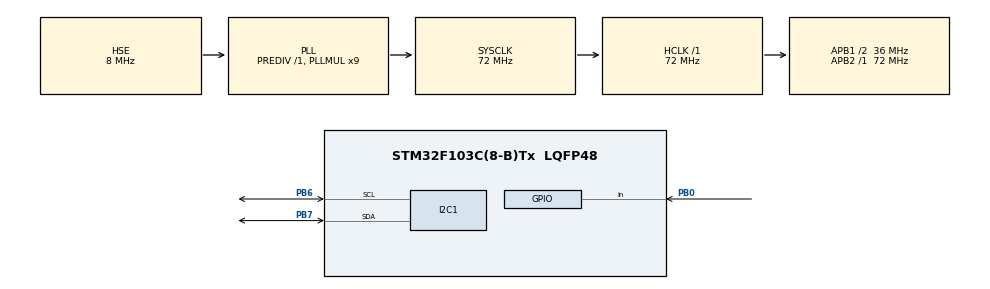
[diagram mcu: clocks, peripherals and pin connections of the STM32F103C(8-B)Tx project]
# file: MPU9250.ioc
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I2C1.I2C_Mode=I2C_Fast
Mcu.Family=STM32F1
Mcu.Name=STM32F103C(8-B)Tx
Mcu.Package=LQFP48
NVIC.PriorityGroup=NVIC_PRIORITYGROUP_4
NVIC.TIM2_IRQn=true\:0\:0\:false\:false\:true\:true\:true\:true
PA13.Mode=Serial_Wire
PA13.Signal=SYS_JTMS-SWDIO
PA14.Mode=Serial_Wire
PA14.Signal=SYS_JTCK-SWCLK
PB0.GPIO_PuPd=GPIO_PULLUP
PB0.Signal=GPIO_Input
PB6.Mode=I2C
PB6.Signal=I2C1_SCL
PB7.Mode=I2C
PB7.Signal=I2C1_SDA
PD0-OSC_IN.Mode=HSE-External-Oscillator
PD0-OSC_IN.Signal=RCC_OSC_IN
PD1-OSC_OUT.Mode=HSE-External-Oscillator
PD1-OSC_OUT.Signal=RCC_OSC_OUT
ProjectManager.HeapSize=0x200
ProjectManager.StackSize=0x400
ProjectManager.TargetToolchain=STM32CubeIDE
RCC.AHBFreq_Value=72000000
RCC.APB1CLKDivider=RCC_HCLK_DIV2
RCC.APB1Freq_Value=36000000
RCC.APB1TimFreq_Value=72000000
RCC.APB2Freq_Value=72000000
RCC.APB2TimFreq_Value=72000000
RCC.HCLKFreq_Value=72000000
RCC.PLLMUL=RCC_PLL_MUL9
RCC.PLLSourceVirtual=RCC_PLLSOURCE_HSE
RCC.SYSCLKFreq_VALUE=72000000
RCC.SYSCLKSource=RCC_SYSCLKSOURCE_PLLCLK
RCC.USBFreq_Value=72000000
TIM2.AutoReloadPreload=TIM_AUTORELOAD_PRELOAD_ENABLE
TIM2.Period=36000
TIM2.Prescaler=1000
VP_TIM2_VS_ClockSourceINT.Mode=Internal
board=custom

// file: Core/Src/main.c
/* USER CODE BEGIN Header */
/**
  ******************************************************************************
  * @file           : main.c
  * @brief          : Main program body
  ******************************************************************************
  * @attention
  *
  * Copyright (c) 2022 STMicroelectronics.
  * All rights reserved.
  *
  * This software is licensed under terms that can be found in the LICENSE file
  * in the root directory of this software component.
  * If no LICENSE file comes with this software, it is provided AS-IS.
  *
  ******************************************************************************
  */
/* USER CODE END Header */
#include "main.h"

/* USER CODE BEGIN Includes */
#include "MPU9250.h"
#include "arrebote.h"
#include <math.h>
/* USER CODE END Includes */

/* USER CODE BEGIN PD */
#define CANT_MUESTRAS	200
#define VAL_MAX			16384
#define K				57.295779//rad a grad

#define PULSADOR_ACTIVO_BAJO	(1)
#define PULSADOR_TICS			(20)
#define PULSADOR_PUERTO			(GPIOB)
#define PULSADOR_PIN			(GPIO_PIN_0)
#define LED_PLACA_PUERTO		(GPIOC)
#define LED_PLACA_PIN			(GPIO_PIN_13)
/* USER CODE END PD */

 I2C_HandleTypeDef hi2c1;

TIM_HandleTypeDef htim2;

/* USER CODE BEGIN PV */
 float Datos, resultado;
 float angulo;
 float aceleracion;
 arrebote pulsador;
 uint8_t mostrar_datos = 0;
 float base = 0;
/* USER CODE END PV */

void SystemClock_Config(void);
static void MX_GPIO_Init(void);
static void MX_I2C1_Init(void);
static void MX_TIM2_Init(void);

int main(void)
{
  /* USER CODE BEGIN 1 */
  uint8_t i = 0;
  float angulo_display;
  static float promedio = 0;
  /* USER CODE END 1 */

  /* MCU Configuration--------------------------------------------------------*/

  /* Reset of all peripherals, Initializes the Flash interface and the Systick. */
  HAL_Init();

  /* Configure the system clock */
  SystemClock_Config();

  /* Initialize all configured peripherals */
  MX_GPIO_Init();
  MX_I2C1_Init();
  MX_TIM2_Init();
  HAL_TIM_Base_Start_IT(&htim2);
  /* USER CODE BEGIN 2 */

  MPU9250_init();//inicializo el sensor
  inicializar_arrebote(&pulsador, PULSADOR_ACTIVO_BAJO, PULSADOR_TICS);

  /* USER CODE END 2 */

  /* Infinite loop */
  /* USER CODE BEGIN WHILE */
  while (1)
  {
	  chequear_arrebote(&pulsador, HAL_GPIO_ReadPin(PULSADOR_PUERTO, PULSADOR_PIN));
	  if(hay_flanco_arrebote(&pulsador))	base = angulo;

	  if(mostrar_datos)//muestro un nuevo angulo cada 500 ms
	  {
	  	for(i = 0; i < CANT_MUESTRAS; i++){
	  		Datos = MPU_readRawData();//Datos: variable que va desde 0 a 65535
	  		promedio +=Datos;
	  	}

	  	promedio /= CANT_MUESTRAS;
	  	aceleracion = (float)promedio/VAL_MAX;
	  	angulo = asinf(aceleracion)*K;//angulo en grados

	  	angulo_display = angulo - base;

	  	//if(seteo_zero) seteo_zero == 0;

	  	promedio = 0;
	  	mostrar_datos = 0;
	  }
    /* USER CODE END WHILE */

  }
}

void HAL_TIM_PeriodElapsedCallback(TIM_HandleTypeDef* htim)
{
    mostrar_datos = 1;
}

void SystemClock_Config(void)
{
  RCC_OscInitTypeDef RCC_OscInitStruct = {0};
  RCC_ClkInitTypeDef RCC_ClkInitStruct = {0};

  /** Initializes the RCC Oscillators according to the specified parameters
  * in the RCC_OscInitTypeDef structure.
  */
  RCC_OscInitStruct.OscillatorType = RCC_OSCILLATORTYPE_HSE;
  RCC_OscInitStruct.HSEState = RCC_HSE_ON;
  RCC_OscInitStruct.HSEPredivValue = RCC_HSE_PREDIV_DIV1;
  RCC_OscInitStruct.HSIState = RCC_HSI_ON;
  RCC_OscInitStruct.PLL.PLLState = RCC_PLL_ON;
  RCC_OscInitStruct.PLL.PLLSource = RCC_PLLSOURCE_HSE;
  RCC_OscInitStruct.PLL.PLLMUL = RCC_PLL_MUL9;
  if (HAL_RCC_OscConfig(&RCC_OscInitStruct) != HAL_OK)
  {
    Error_Handler();
  }

  /** Initializes the CPU, AHB and APB buses clocks
  */
  RCC_ClkInitStruct.ClockType = RCC_CLOCKTYPE_HCLK|RCC_CLOCKTYPE_SYSCLK
                              |RCC_CLOCKTYPE_PCLK1|RCC_CLOCKTYPE_PCLK2;
  RCC_ClkInitStruct.SYSCLKSource = RCC_SYSCLKSOURCE_PLLCLK;
  RCC_ClkInitStruct.AHBCLKDivider = RCC_SYSCLK_DIV1;
  RCC_ClkInitStruct.APB1CLKDivider = RCC_HCLK_DIV2;
  RCC_ClkInitStruct.APB2CLKDivider = RCC_HCLK_DIV1;

  if (HAL_RCC_ClockConfig(&RCC_ClkInitStruct, FLASH_LATENCY_2) != HAL_OK)
  {
    Error_Handler();
  }
}

static void MX_I2C1_Init(void)
{

  hi2c1.Instance = I2C1;
  hi2c1.Init.ClockSpeed = 400000;
  hi2c1.Init.DutyCycle = I2C_DUTYCYCLE_2;
  hi2c1.Init.OwnAddress1 = 0;
  hi2c1.Init.AddressingMode = I2C_ADDRESSINGMODE_7BIT;
  hi2c1.Init.DualAddressMode = I2C_DUALADDRESS_DISABLE;
  hi2c1.Init.OwnAddress2 = 0;
  hi2c1.Init.GeneralCallMode = I2C_GENERALCALL_DISABLE;
  hi2c1.Init.NoStretchMode = I2C_NOSTRETCH_DISABLE;
  if (HAL_I2C_Init(&hi2c1) != HAL_OK)
  {
    Error_Handler();
  }

}

static void MX_TIM2_Init(void)
{

  TIM_ClockConfigTypeDef sClockSourceConfig = {0};
  TIM_MasterConfigTypeDef sMasterConfig = {0};

  htim2.Instance = TIM2;
  htim2.Init.Prescaler = 1000;
  htim2.Init.CounterMode = TIM_COUNTERMODE_UP;
  htim2.Init.Period = 36000;
  htim2.Init.ClockDivision = TIM_CLOCKDIVISION_DIV1;
  htim2.Init.AutoReloadPreload = TIM_AUTORELOAD_PRELOAD_ENABLE;
  if (HAL_TIM_Base_Init(&htim2) != HAL_OK)
  {
    Error_Handler();
  }
  sClockSourceConfig.ClockSource = TIM_CLOCKSOURCE_INTERNAL;
  if (HAL_TIM_ConfigClockSource(&htim2, &sClockSourceConfig) != HAL_OK)
  {
    Error_Handler();
  }
  sMasterConfig.MasterOutputTrigger = TIM_TRGO_RESET;
  sMasterConfig.MasterSlaveMode = TIM_MASTERSLAVEMODE_DISABLE;
  if (HAL_TIMEx_MasterConfigSynchronization(&htim2, &sMasterConfig) != HAL_OK)
  {
    Error_Handler();
  }

}

static void MX_GPIO_Init(void)
{
  GPIO_InitTypeDef GPIO_InitStruct = {0};

  /* GPIO Ports Clock Enable */
  __HAL_RCC_GPIOD_CLK_ENABLE();
  __HAL_RCC_GPIOB_CLK_ENABLE();
  __HAL_RCC_GPIOA_CLK_ENABLE();

  /*Configure GPIO pin : PB0 */
  GPIO_InitStruct.Pin = GPIO_PIN_0;
  GPIO_InitStruct.Mode = GPIO_MODE_INPUT;
  GPIO_InitStruct.Pull = GPIO_PULLUP;
  HAL_GPIO_Init(GPIOB, &GPIO_InitStruct);

}

void Error_Handler(void)
{
  __disable_irq();
  while (1)
  {
  }
}
